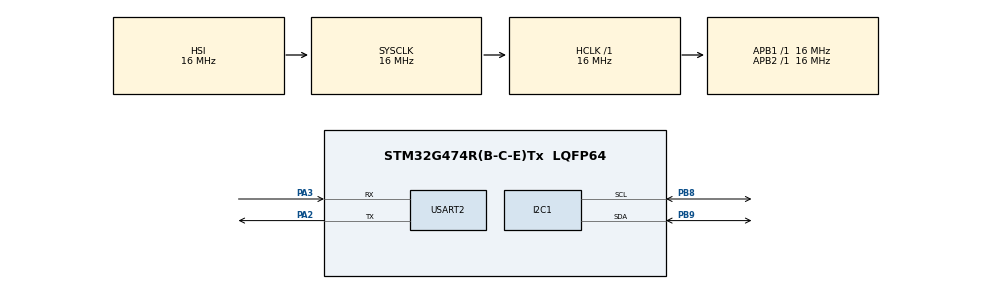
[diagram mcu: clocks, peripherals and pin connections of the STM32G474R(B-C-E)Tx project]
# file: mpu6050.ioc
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I2C1.Timing=0x00503D58
Mcu.Family=STM32G4
Mcu.Name=STM32G474R(B-C-E)Tx
Mcu.Package=LQFP64
NVIC.PriorityGroup=NVIC_PRIORITYGROUP_4
PA2.Mode=Asynchronous
PA2.Signal=USART2_TX
PA3.Mode=Asynchronous
PA3.Signal=USART2_RX
PB8-BOOT0.Mode=I2C
PB8-BOOT0.Signal=I2C1_SCL
PB9.Mode=I2C
PB9.Signal=I2C1_SDA
ProjectManager.HeapSize=0x200
ProjectManager.StackSize=0x400
ProjectManager.TargetToolchain=STM32CubeIDE
RCC.AHBFreq_Value=16000000
RCC.APB1Freq_Value=16000000
RCC.APB1TimFreq_Value=16000000
RCC.APB2Freq_Value=16000000
RCC.APB2TimFreq_Value=16000000
RCC.CortexFreq_Value=16000000
RCC.EXTERNAL_CLOCK_VALUE=12288000
RCC.HCLKFreq_Value=16000000
RCC.HSE_VALUE=8000000
RCC.HSI48_VALUE=48000000
RCC.HSI_VALUE=16000000
RCC.LSE_VALUE=32768
RCC.SYSCLKFreq_VALUE=16000000
RCC.USBFreq_Value=64000000
RCC.VCOOutputFreq_Value=128000000
USART2.VirtualMode-Asynchronous=VM_ASYNC
VP_SYS_VS_DBSignals.Mode=DisableDeadBatterySignals
board=custom

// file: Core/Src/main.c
/* USER CODE BEGIN Header */
/**
 ******************************************************************************
 * @file           : main.c
 * @brief          : Main program body
 ******************************************************************************
 * @attention
 *
 * Copyright (c) 2026 STMicroelectronics.
 * All rights reserved.
 *
 * This software is licensed under terms that can be found in the LICENSE file
 * in the root directory of this software component.
 * If no LICENSE file comes with this software, it is provided AS-IS.
 *
 ******************************************************************************
 */
/* USER CODE END Header */
#include "main.h"
#include "i2c.h"
#include "usart.h"
#include "gpio.h"

/* USER CODE BEGIN Includes */
#include "stdio.h"
#include "app.h"
#include "system_context.h"
/* USER CODE END Includes */

/* USER CODE BEGIN PV */
SystemContext_t system;
/* USER CODE END PV */

void SystemClock_Config(void);

/* USER CODE BEGIN 0 */

int __io_putchar(int ch) {
	HAL_UART_Transmit(&huart2, (uint8_t*) &ch, 1, HAL_MAX_DELAY);
	return ch;
}
/* USER CODE END 0 */

int main(void) {

	/* MCU Configuration--------------------------------------------------------*/

	/* Reset of all peripherals, Initializes the Flash interface and the Systick. */
	HAL_Init();

	/* Configure the system clock */
	SystemClock_Config();

	/* Initialize all configured peripherals */
	MX_GPIO_Init();
	MX_I2C1_Init();
	MX_USART2_UART_Init();
	/* USER CODE BEGIN 2 */

	system.hardware.hi2c1 = &hi2c1;
	system.hardware.huart2 = &huart2;

	APP_Init(&system);
	/* USER CODE END 2 */

	/* Infinite loop */
	/* USER CODE BEGIN WHILE */
	while (1) {

		APP_Run();

	}
	/* USER CODE END WHILE */

}

void SystemClock_Config(void) {
	RCC_OscInitTypeDef RCC_OscInitStruct = { 0 };
	RCC_ClkInitTypeDef RCC_ClkInitStruct = { 0 };

	/** Configure the main internal regulator output voltage
	 */
	HAL_PWREx_ControlVoltageScaling(PWR_REGULATOR_VOLTAGE_SCALE1);

	/** Initializes the RCC Oscillators according to the specified parameters
	 * in the RCC_OscInitTypeDef structure.
	 */
	RCC_OscInitStruct.OscillatorType = RCC_OSCILLATORTYPE_HSI;
	RCC_OscInitStruct.HSIState = RCC_HSI_ON;
	RCC_OscInitStruct.HSICalibrationValue = RCC_HSICALIBRATION_DEFAULT;
	RCC_OscInitStruct.PLL.PLLState = RCC_PLL_NONE;
	if (HAL_RCC_OscConfig(&RCC_OscInitStruct) != HAL_OK) {
		Error_Handler();
	}

	/** Initializes the CPU, AHB and APB buses clocks
	 */
	RCC_ClkInitStruct.ClockType = RCC_CLOCKTYPE_HCLK | RCC_CLOCKTYPE_SYSCLK
			| RCC_CLOCKTYPE_PCLK1 | RCC_CLOCKTYPE_PCLK2;
	RCC_ClkInitStruct.SYSCLKSource = RCC_SYSCLKSOURCE_HSI;
	RCC_ClkInitStruct.AHBCLKDivider = RCC_SYSCLK_DIV1;
	RCC_ClkInitStruct.APB1CLKDivider = RCC_HCLK_DIV1;
	RCC_ClkInitStruct.APB2CLKDivider = RCC_HCLK_DIV1;

	if (HAL_RCC_ClockConfig(&RCC_ClkInitStruct, FLASH_LATENCY_0) != HAL_OK) {
		Error_Handler();
	}
}

void Error_Handler(void) {
	__disable_irq();
	while (1) {
	}
}
